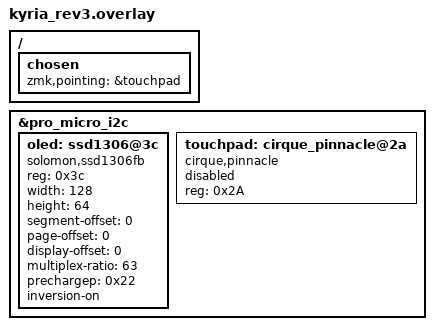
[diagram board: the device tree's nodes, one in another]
/ {
    chosen {
        zmk,pointing = &touchpad;
    };
};

&pro_micro_i2c {
    status = "okay";

    oled: ssd1306@3c {
        compatible = "solomon,ssd1306fb";
        reg = <0x3c>;
        width = <128>;
        height = <64>;
        segment-offset = <0>;
        page-offset = <0>;
        display-offset = <0>;
        multiplex-ratio = <63>;
        prechargep = <0x22>;
        inversion-on;
    };

    touchpad: cirque_pinnacle@2a {
        compatible = "cirque,pinnacle";
        reg = <0x2A>;
        status = "disabled";
    };
}
